AUTOSAR XML (schema 00044)
standard types defined: boolean, float32, float64, sint16, sint32, sint64, sint8, uint16, uint32, uint64, uint8
package /AUTOSAR_Platform/CompuMethods
  compu method CompuMethod_boolean: 0=FALSE, 1=TRUE
package /AUTOSAR_Platform/DataConstrs
  range DataConstr_boolean: raw 0..1
  range DataConstr_float32: raw -3.4028235e+38..3.4028235e+38
  range DataConstr_float64: raw -1.7976931348623157e+308..1.7976931348623157e+308
  range DataConstr_sint16: raw -32768..32767
  range DataConstr_sint32: raw -2147483648..2147483647
  range DataConstr_sint64: raw -9223372036854775808..9223372036854775807
  range DataConstr_sint8: raw -128..127
  range DataConstr_uint16: raw 0..65535
  range DataConstr_uint32: raw 0..4294967295
  range DataConstr_uint64: raw 0..18446744073709551615
  range DataConstr_uint8: raw 0..255
package /VW/Global/PhysicalDimensions
  physical dimension PD_undefined_unit_helper_nounit
package /VW/Global/Units
  unit Unit_nounit: display-name=nounit, factor-si-to-unit=1.0, offset-si-to-unit=0, physical-dimension=PD_undefined_unit_helper_nounit
package /com/applied/arche/lights/ApplicationDataTypes
  app type ADT_boolean: category=BOOLEAN, compu {0=FALSE, 1=TRUE}
package /com/applied/arche/lights/ConstantSpecifications
  constant specification C_INIT_IF_ALU_L_440_PWM_DE_ALU_L_440_PWM: value-spec=0
  constant specification C_INIT_IF_ALU_R_400_PWM_DE_ALU_R_400_PWM: value-spec=0
package /com/applied/arche/lights/PortInterfaces
  sender receiver interface IF_ALU_L_440_PWM
    data DE_ALU_L_440_PWM
  sender receiver interface IF_ALU_R_400_PWM
    data DE_ALU_R_400_PWM
package /com/applied/arche/lights/SwComponentTypes
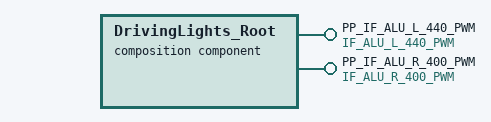
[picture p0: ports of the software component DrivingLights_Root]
  composition sw component type DrivingLights_Root
    provide port PP_IF_ALU_L_440_PWM: nonqueued-sender-com-spec{data-element=DE_ALU_L_440_PWM, init-value=constant-reference=C_INIT_IF_ALU_L_440_PWM_DE_ALU_L_440_PWM}, provided-interface=IF_ALU_L_440_PWM
    provide port PP_IF_ALU_R_400_PWM: nonqueued-sender-com-spec{data-element=DE_ALU_R_400_PWM, init-value=constant-reference=C_INIT_IF_ALU_R_400_PWM_DE_ALU_R_400_PWM}, provided-interface=IF_ALU_R_400_PWM
